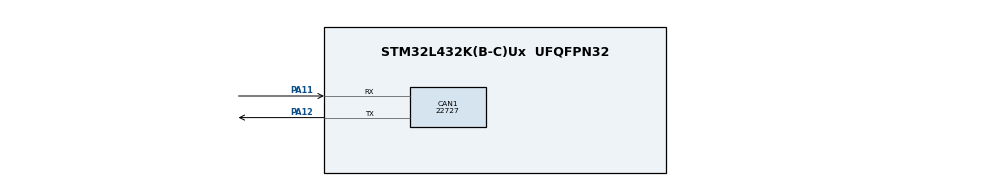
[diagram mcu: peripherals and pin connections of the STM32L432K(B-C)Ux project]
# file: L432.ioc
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CAN1.BS1=CAN_BS1_8TQ
CAN1.BS2=CAN_BS2_2TQ
CAN1.CalculateBaudRate=22727
CAN1.CalculateTimeBit=44000
CAN1.CalculateTimeQuantum=4000.0
Mcu.Family=STM32L4
Mcu.Name=STM32L432K(B-C)Ux
Mcu.Package=UFQFPN32
NVIC.CAN1_RX0_IRQn=true\:0\:0\:false\:false\:true\:true\:true\:true
NVIC.CAN1_RX1_IRQn=true\:0\:0\:false\:false\:true\:true\:true\:true
NVIC.CAN1_SCE_IRQn=true\:0\:0\:false\:false\:true\:true\:true\:true
NVIC.CAN1_TX_IRQn=true\:0\:0\:false\:false\:true\:true\:true\:true
NVIC.PriorityGroup=NVIC_PRIORITYGROUP_4
PA11.Mode=CAN_Activate
PA11.Signal=CAN1_RX
PA12.Mode=CAN_Activate
PA12.Signal=CAN1_TX
ProjectManager.HeapSize=0x200
ProjectManager.StackSize=0x400
ProjectManager.TargetToolchain=STM32CubeIDE
RCC.HSE_VALUE=8000000
RCC.HSI48_VALUE=48000000
RCC.HSI_VALUE=16000000
RCC.LSE_VALUE=32768
RCC.MSI_VALUE=4000000
RCC.VCOOutputFreq_Value=32000000
board=custom

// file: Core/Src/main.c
/* USER CODE BEGIN Header */
/**
 ******************************************************************************
 * @file           : main.c
 * @brief          : Main program body
 * @author 		   : Theo RUSINOWITCH <teo.rusi@hotmail.fr>
 ******************************************************************************
 * @attention
 *
 * <h2><center>&copy; Copyright (c) 2021 STMicroelectronics.
 * All rights reserved.</center></h2>
 *
 * This software component is licensed by ST under BSD 3-Clause license,
 * the "License"; You may not use this file except in compliance with the
 * License. You may obtain a copy of the License at:
 *                        opensource.org/licenses/BSD-3-Clause
 *
 ******************************************************************************
 */
/* USER CODE END Header */
#include "main.h"

/* USER CODE BEGIN Includes */
#include "can.h"
/* USER CODE END Includes */

CAN_HandleTypeDef hcan1;

void SystemClock_Config(void);
static void MX_GPIO_Init(void);
static void MX_CAN1_Init(void);

int main(void)
{

  /* MCU Configuration--------------------------------------------------------*/

  /* Reset of all peripherals, Initializes the Flash interface and the Systick. */
  HAL_Init();

  /* Configure the system clock */
  SystemClock_Config();

  /* Initialize all configured peripherals */
  MX_GPIO_Init();
  MX_CAN1_Init();
  /* USER CODE BEGIN 2 */
  configure_CAN(&hcan1, CAN_ADDR_ODOMETRIE);
  /* USER CODE END 2 */

  /* Infinite loop */
	while (1) {

	}
}

void SystemClock_Config(void)
{
  RCC_OscInitTypeDef RCC_OscInitStruct = {0};
  RCC_ClkInitTypeDef RCC_ClkInitStruct = {0};

  /** Configure the main internal regulator output voltage
  */
  if (HAL_PWREx_ControlVoltageScaling(PWR_REGULATOR_VOLTAGE_SCALE1) != HAL_OK)
  {
    Error_Handler();
  }

  /** Initializes the RCC Oscillators according to the specified parameters
  * in the RCC_OscInitTypeDef structure.
  */
  RCC_OscInitStruct.OscillatorType = RCC_OSCILLATORTYPE_MSI;
  RCC_OscInitStruct.MSIState = RCC_MSI_ON;
  RCC_OscInitStruct.MSICalibrationValue = 0;
  RCC_OscInitStruct.MSIClockRange = RCC_MSIRANGE_6;
  RCC_OscInitStruct.PLL.PLLState = RCC_PLL_NONE;
  if (HAL_RCC_OscConfig(&RCC_OscInitStruct) != HAL_OK)
  {
    Error_Handler();
  }

  /** Initializes the CPU, AHB and APB buses clocks
  */
  RCC_ClkInitStruct.ClockType = RCC_CLOCKTYPE_HCLK|RCC_CLOCKTYPE_SYSCLK
                              |RCC_CLOCKTYPE_PCLK1|RCC_CLOCKTYPE_PCLK2;
  RCC_ClkInitStruct.SYSCLKSource = RCC_SYSCLKSOURCE_MSI;
  RCC_ClkInitStruct.AHBCLKDivider = RCC_SYSCLK_DIV1;
  RCC_ClkInitStruct.APB1CLKDivider = RCC_HCLK_DIV1;
  RCC_ClkInitStruct.APB2CLKDivider = RCC_HCLK_DIV1;

  if (HAL_RCC_ClockConfig(&RCC_ClkInitStruct, FLASH_LATENCY_0) != HAL_OK)
  {
    Error_Handler();
  }
}

static void MX_CAN1_Init(void)
{

  hcan1.Instance = CAN1;
  hcan1.Init.Prescaler = 16;
  hcan1.Init.Mode = CAN_MODE_NORMAL;
  hcan1.Init.SyncJumpWidth = CAN_SJW_1TQ;
  hcan1.Init.TimeSeg1 = CAN_BS1_8TQ;
  hcan1.Init.TimeSeg2 = CAN_BS2_2TQ;
  hcan1.Init.TimeTriggeredMode = DISABLE;
  hcan1.Init.AutoBusOff = DISABLE;
  hcan1.Init.AutoWakeUp = DISABLE;
  hcan1.Init.AutoRetransmission = DISABLE;
  hcan1.Init.ReceiveFifoLocked = DISABLE;
  hcan1.Init.TransmitFifoPriority = DISABLE;
  if (HAL_CAN_Init(&hcan1) != HAL_OK)
  {
    Error_Handler();
  }

}

static void MX_GPIO_Init(void)
{

  /* GPIO Ports Clock Enable */
  __HAL_RCC_GPIOA_CLK_ENABLE();

}

void Error_Handler(void)
{
	__disable_irq();
	while (1) {
	}
}
